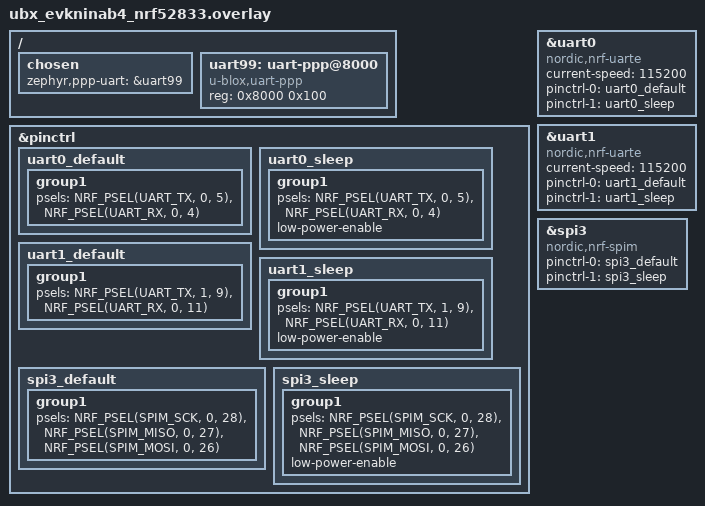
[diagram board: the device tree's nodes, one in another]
/* This configuration is specifically modified for the tests as run on a NRF52833 board wired in the u-blox test system. */
/* For default settings, refer to the file of the same name in the boards/arm directory of Zephyr. */

&pinctrl {
    uart0_default: uart0_default {
        group1 {
            psels = <NRF_PSEL(UART_TX, 0, 5)>,
                    <NRF_PSEL(UART_RX, 0, 4)>;
        };
    };

    uart0_sleep: uart0_sleep {
        group1 {
            psels = <NRF_PSEL(UART_TX, 0, 5)>,
                    <NRF_PSEL(UART_RX, 0, 4)>;
            low-power-enable;
        };
    };

    uart1_default: uart1_default {
        group1 {
            psels = <NRF_PSEL(UART_TX, 1, 9)>,
                    <NRF_PSEL(UART_RX, 0, 11)>;
        };
    };

    uart1_sleep: uart1_sleep {
        group1 {
            psels = <NRF_PSEL(UART_TX, 1, 9)>,
                    <NRF_PSEL(UART_RX, 0, 11)>;
            low-power-enable;
        };
    };

    spi3_default: spi3_default {
        group1 {
            psels = <NRF_PSEL(SPIM_SCK, 0, 28)>,
                    <NRF_PSEL(SPIM_MISO, 0, 27)>,
                    <NRF_PSEL(SPIM_MOSI, 0, 26)>;
        };
    };

    spi3_sleep: spi3_sleep {
        group1 {
            psels = <NRF_PSEL(SPIM_SCK, 0, 28)>,
                    <NRF_PSEL(SPIM_MISO, 0, 27)>,
                    <NRF_PSEL(SPIM_MOSI, 0, 26)>;
            low-power-enable;
        };
    };

};

&uart0 {
    compatible = "nordic,nrf-uarte";
    status = "okay";
    current-speed = <115200>;
    pinctrl-0 = <&uart0_default>;
    pinctrl-1 = <&uart0_sleep>;
    pinctrl-names = "default", "sleep";
};

&uart1 {
    compatible = "nordic,nrf-uarte";
    status = "okay";
    current-speed = <115200>;
    pinctrl-0 = <&uart1_default>;
    pinctrl-1 = <&uart1_sleep>;
    pinctrl-names = "default", "sleep";
};

&spi3 {
	compatible = "nordic,nrf-spim";
	status = "okay";
	pinctrl-0 = <&spi3_default>;
	pinctrl-1 = <&spi3_sleep>;
	pinctrl-names = "default", "sleep";
};

/* Required for PPP-level integration with ubxlib to work */
/ { // The leading / indicates that we're in the root section
    // This chooses uart instance 99 to be the zephyr,ppp-uart that ppp.c wants
    chosen {
        zephyr,ppp-uart = &uart99;
    };

    // This creates instance 99 of a uart that we will give to zephyr,ppp-uart
    uart99: uart-ppp@8000 { // The "8000" here is irrelevant but required for Zephyr to work
        compatible = "u-blox,uart-ppp"; // The important part: this is an instance of u-blox,uart-ppp
        reg = <0x8000 0x100>; // This is irrelevant but required for Zephyr to work
        status = "okay"; // Zephyr boiler-plate
    };
};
